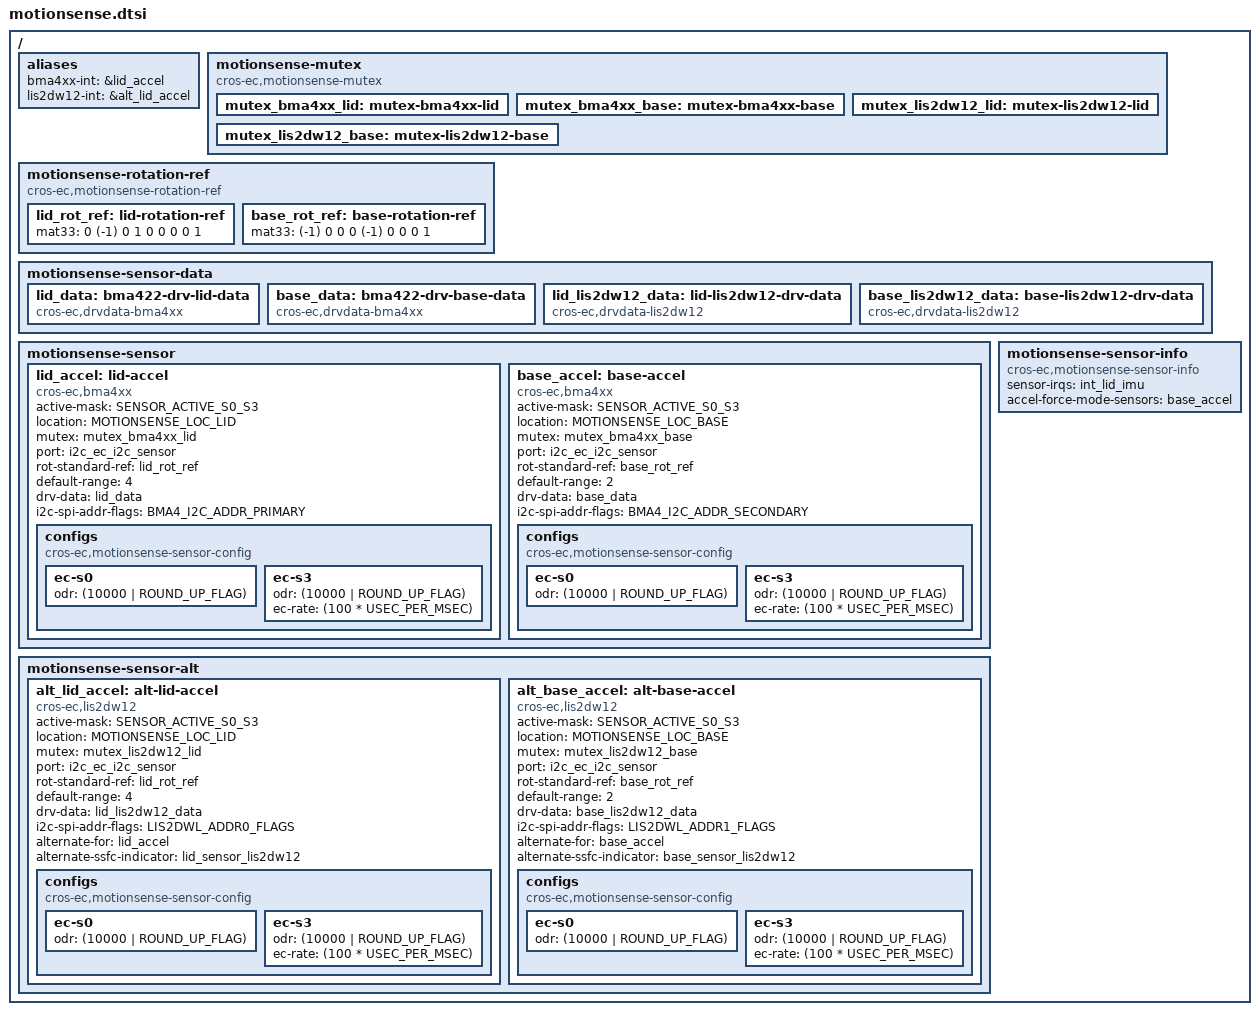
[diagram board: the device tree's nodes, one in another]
/* Copyright 2023 The ChromiumOS Authors
 * Use of this source code is governed by a BSD-style license that can be
 * found in the LICENSE file.
 */

#include <dt-bindings/motionsense/utils.h>

/ {
	aliases {
		/*
		 * motion sense's <>_INT_EVENT is handled by alias. Using the
		 * alias, each driver creates its own <>_INT_EVENT.
		 */
		 bma4xx-int = &lid_accel;
		 lis2dw12-int = &alt_lid_accel;
	};

	/*
	 * Declare mutexes used by sensor drivers.
	 * A mutex node is used to create an instance of mutex_t.
	 * A mutex node is referenced by a sensor node if the
	 * corresponding sensor driver needs to use the
	 * instance of the mutex.
	 */
	motionsense-mutex {
		compatible = "cros-ec,motionsense-mutex";
		mutex_bma4xx_lid: mutex-bma4xx-lid {
		};
		mutex_bma4xx_base: mutex-bma4xx-base {
		};
		mutex_lis2dw12_lid: mutex-lis2dw12-lid {
		};
		mutex_lis2dw12_base: mutex-lis2dw12-base {
		};
	};

	/* Rotation matrix used by drivers. */
	motionsense-rotation-ref {
		compatible = "cros-ec,motionsense-rotation-ref";
		lid_rot_ref: lid-rotation-ref {
			mat33 = <0 (-1) 0
				 1 0 0
				 0 0 1>;
		};
		base_rot_ref: base-rotation-ref {
			mat33 = <(-1) 0 0
				 0 (-1) 0
				 0 0 1>;
		};
	};

	/*
	 * Driver specific data. A driver-specific data can be shared with
	 * different motion sensors while they are using the same driver.
	 *
	 * If a node's compatible starts with "cros-ec,accelgyro-", it is for
	 * a common structure defined in accelgyro.h.
	 * e.g) compatible = "cros-ec,accelgyro-als-drv-data" is for
	 * "struct als_drv_data_t" in accelgyro.h
	 */
	motionsense-sensor-data {
		lid_data: bma422-drv-lid-data {
			compatible = "cros-ec,drvdata-bma4xx";
			status = "okay";
		};
		base_data: bma422-drv-base-data {
			compatible = "cros-ec,drvdata-bma4xx";
			status = "okay";
		};
		lid_lis2dw12_data: lid-lis2dw12-drv-data {
			compatible = "cros-ec,drvdata-lis2dw12";
			status = "okay";
		};
		base_lis2dw12_data: base-lis2dw12-drv-data {
			compatible = "cros-ec,drvdata-lis2dw12";
			status = "okay";
		};
	};

	/*
	 * List of motion sensors that creates motion_sensors array.
	 * The nodelabel "lid_accel" and "base_accel" are used to indicate
	 * motion sensor IDs for lid angle calculation.
	 * TODO(b/238139272): The first entries of the array must be
	 * accelerometers,then gyroscope. Fix this dependency in the DTS
	 * processing which makes the devicetree entries independent.
	 */
	motionsense-sensor {
		lid_accel: lid-accel {
			compatible = "cros-ec,bma4xx";
			status = "okay";

			active-mask = "SENSOR_ACTIVE_S0_S3";
			location = "MOTIONSENSE_LOC_LID";
			mutex = <&mutex_bma4xx_lid>;
			port = <&i2c_ec_i2c_sensor>;
			rot-standard-ref = <&lid_rot_ref>;
			default-range = <4>; /* to meet CDD 7.3.1/C-1-4 reqs. */
			drv-data = <&lid_data>;
			i2c-spi-addr-flags = "BMA4_I2C_ADDR_PRIMARY";
			configs {
				compatible =
					"cros-ec,motionsense-sensor-config";
				ec-s0 {
					odr = <(10000 | ROUND_UP_FLAG)>;
				};
				ec-s3 {
					odr = <(10000 | ROUND_UP_FLAG)>;
					ec-rate = <(100 * USEC_PER_MSEC)>;
				};
			};
		};

		base_accel: base-accel {
			compatible = "cros-ec,bma4xx";
			status = "okay";

			active-mask = "SENSOR_ACTIVE_S0_S3";
			location = "MOTIONSENSE_LOC_BASE";
			mutex = <&mutex_bma4xx_base>;
			port = <&i2c_ec_i2c_sensor>;
			rot-standard-ref = <&base_rot_ref>;
			default-range = <2>;
			drv-data = <&base_data>;
			i2c-spi-addr-flags = "BMA4_I2C_ADDR_SECONDARY";
			configs {
				compatible =
					"cros-ec,motionsense-sensor-config";
				ec-s0 {
					odr = <(10000 | ROUND_UP_FLAG)>;
				};
				ec-s3 {
					odr = <(10000 | ROUND_UP_FLAG)>;
					ec-rate = <(100 * USEC_PER_MSEC)>;
				};
			};
		};
	};

	/* List of motion sensors that creates motion_sensors array. */
	motionsense-sensor-alt {
		alt_lid_accel: alt-lid-accel {
			compatible = "cros-ec,lis2dw12";
			status = "okay";

			active-mask = "SENSOR_ACTIVE_S0_S3";
			location = "MOTIONSENSE_LOC_LID";
			mutex = <&mutex_lis2dw12_lid>;
			port = <&i2c_ec_i2c_sensor>;
			rot-standard-ref = <&lid_rot_ref>;
			default-range = <4>; /* to meet CDD 7.3.1/C-1-4 reqs. */
			drv-data = <&lid_lis2dw12_data>;
			i2c-spi-addr-flags = "LIS2DWL_ADDR0_FLAGS";
			alternate-for = <&lid_accel>;
			alternate-ssfc-indicator = <&lid_sensor_lis2dw12>;
			configs {
				compatible =
					"cros-ec,motionsense-sensor-config";
				ec-s0 {
					odr = <(10000 | ROUND_UP_FLAG)>;
				};
				ec-s3 {
					odr = <(10000 | ROUND_UP_FLAG)>;
					ec-rate = <(100 * USEC_PER_MSEC)>;
				};
			};
		};

		alt_base_accel: alt-base-accel {
			compatible = "cros-ec,lis2dw12";
			status = "okay";

			active-mask = "SENSOR_ACTIVE_S0_S3";
			location = "MOTIONSENSE_LOC_BASE";
			mutex = <&mutex_lis2dw12_base>;
			port = <&i2c_ec_i2c_sensor>;
			rot-standard-ref = <&base_rot_ref>;
			default-range = <2>;
			drv-data = <&base_lis2dw12_data>;
			i2c-spi-addr-flags = "LIS2DWL_ADDR1_FLAGS";
			alternate-for = <&base_accel>;
			alternate-ssfc-indicator = <&base_sensor_lis2dw12>;
			configs {
				compatible =
					"cros-ec,motionsense-sensor-config";
				ec-s0 {
					odr = <(10000 | ROUND_UP_FLAG)>;
				};
				ec-s3 {
					odr = <(10000 | ROUND_UP_FLAG)>;
					ec-rate = <(100 * USEC_PER_MSEC)>;
				};
			};
		};
	};

	/* High level description info */
	motionsense-sensor-info {
		compatible = "cros-ec,motionsense-sensor-info";

		/*
		 * List of GPIO interrupts that have to be enabled at initial
		 * stage.sensor_alt_id
		 */
		sensor-irqs = <&int_lid_imu>;

		/* List of sensors in force mode */
		accel-force-mode-sensors = <&base_accel>;
	};
};
